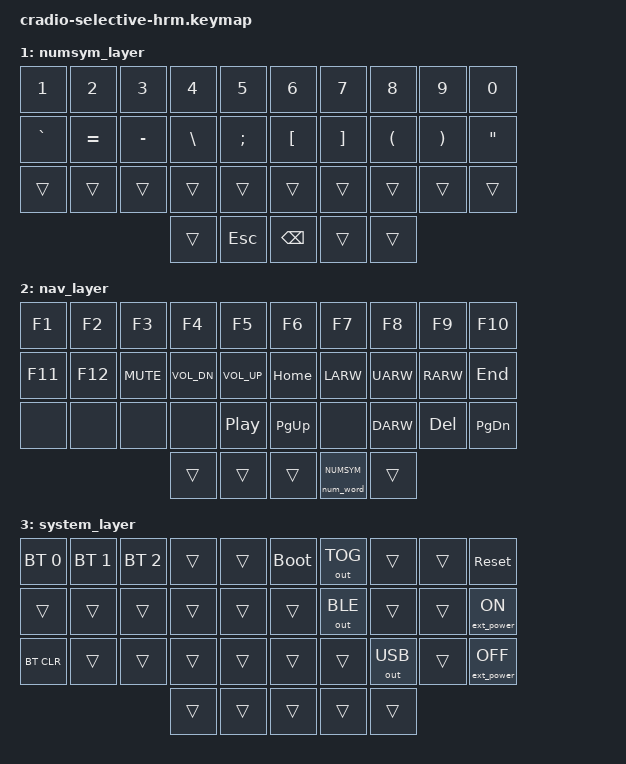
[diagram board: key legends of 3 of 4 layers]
// Copyright (c) 2022 The ZMK Contributors
// SPDX-License-Identifier: MIT
//
// OPTION 2: SELECTIVE HOME ROW MODS (RECOMMENDED)
// - SHIFT moved to left thumb (sticky behavior)
// - CTRL added to right thumb cluster for vim
// - Only CMD/ALT remain on home row (with longer delays)
// - Panic mode for layer recovery
// - Solves the biggest HRM typing interference issues

#include <behaviors/num_word.dtsi>
#include <behaviors.dtsi>
#include <dt-bindings/zmk/keys.h>
#include <dt-bindings/zmk/bt.h>
#include <dt-bindings/zmk/outputs.h>
#include <dt-bindings/zmk/ext_power.h>

// ---------- Layer indexes ----------
#define BASE    0 
#define NUMSYM  1
#define NAV     2
#define SYSTEM  3

// ---------- Reduced Home-row Mods (CMD/ALT only) ----------
#define HRML_LITE(k1,k2,k3,k4) &kp k1  &ht_slow LALT k2   &kp k3   &ht_slow LGUI k4
#define HRMR_LITE(k1,k2,k3,k4) &ht_slow RGUI k1   &kp k2  &ht_slow RALT k3    &kp k4

/ {
    behaviors {
        // Standard hold-tap for layer access
        ht: hold_tap {
            compatible = "zmk,behavior-hold-tap";
            #binding-cells = <2>;
            flavor = "tap-preferred";
            tapping-term-ms = <200>;
            quick-tap-ms = <120>;
            require-prior-idle-ms = <100>;
            bindings = <&kp>, <&kp>;
        };

        // Slower hold-tap for remaining home row mods to prevent roll interference
        ht_slow: hold_tap_slow {
            compatible = "zmk,behavior-hold-tap";
            #binding-cells = <2>;
            flavor = "tap-preferred";
            tapping-term-ms = <280>;  // Longer delay
            quick-tap-ms = <100>;
            require-prior-idle-ms = <150>;  // More idle time
            bindings = <&kp>, <&kp>;
        };

        // Sticky SHIFT - tap for next key, hold for continuous
        sk_lshft: sticky_shift {
            compatible = "zmk,behavior-sticky-key";
            #binding-cells = <1>;
            bindings = <&kp>;
            release-after-ms = <1000>;
            quick-release;
        };

        // Sticky CTRL for vim workflows
        sk_lctrl: sticky_ctrl {
            compatible = "zmk,behavior-sticky-key";
            #binding-cells = <1>;
            bindings = <&kp>;
            release-after-ms = <1000>;
            quick-release;
        };

        // Multi-function thumb key: hold for sticky, tap for regular
        mt_shift: mod_tap_shift {
            compatible = "zmk,behavior-hold-tap";
            #binding-cells = <2>;
            flavor = "tap-preferred";
            tapping-term-ms = <200>;
            quick-tap-ms = <120>;
            require-prior-idle-ms = <100>;
            bindings = <&sk_lshft>, <&kp>;
        };

        mt_ctrl: mod_tap_ctrl {
            compatible = "zmk,behavior-hold-tap";
            #binding-cells = <2>;
            flavor = "tap-preferred";
            tapping-term-ms = <200>;
            quick-tap-ms = <120>;
            require-prior-idle-ms = <100>;
            bindings = <&sk_lctrl>, <&kp>;
        };
    };

    // ---------- Combos for enhanced functionality ----------
    combos {
        compatible = "zmk,combos";
        
        // Panic mode - double thumb tap returns to base
        combo_panic {
            timeout-ms = <50>;
            key-positions = <30 33>;
            bindings = <&to BASE>;
            layers = <BASE NUMSYM NAV SYSTEM>;
        };

        // Common shortcuts as combos
        combo_enter {
            timeout-ms = <40>;
            key-positions = <17 18 19>; // J K L
            bindings = <&kp ENTER>;
            layers = <BASE>;
        };

        combo_hyphen {
            timeout-ms = <40>;
            key-positions = <22 23>; // C V
            bindings = <&kp MINUS>;
            layers = <BASE>;
        };

        combo_underscore {
            timeout-ms = <40>;
            key-positions = <22 23>; // C V
            bindings = <&kp UNDER>;
            layers = <NUMSYM>;
        };
    };

    // ---------- Conditional tri-layer ----------
    conditional_layers {
        compatible = "zmk,conditional-layers";
        system_layer {
            if-layers = <NAV NUMSYM>;
            then-layer = <SYSTEM>;
        };
    };

    keymap {
        compatible = "zmk,keymap";
        base_layer {
            bindings = <
        //╭──────────┬──────────┬──────────┬──────────┬──────────╮   ╭──────────┬──────────┬──────────┬──────────┬──────────╮
        //│  Q       │  W       │  E       │  R       │  T       │   │  Y       │  U       │  I       │  O       │  P       │
             &kp Q      &kp W      &kp E      &kp R      &kp T          &kp Y      &kp U      &kp I      &kp O      &kp P
        //├──────────┼──────────┼──────────┼──────────┼──────────┤   ├──────────┼──────────┼──────────┼──────────┼──────────┤
        //│  A       │  S       │  D       │  F       │  G       │   │  H       │  J       │  K       │  L       │ ' "      │
             HRML_LITE(A, S,       D,         F)         &kp G          &kp H      HRMR_LITE(J, K,       L,        SQT)
        //├──────────┼──────────┼──────────┼──────────┼──────────┤   ├──────────┼──────────┼──────────┼──────────┼──────────┤
        //│  Z       │  X       │  C       │  V       │  B       │   │  N       │  M       │ , <      │ . >      │ / ?      │
            &kp Z      &kp X      &kp C      &kp V      &kp B          &kp N      &kp M      &kp COMMA  &kp DOT    &kp FSLH
        //╰──────────┴──────────┴──────────┼──────────┼──────────┤   ├──────────┼──────────┼──────────┴──────────┴──────────╯
                                    &mt_shift LSHFT &lt NAV TAB     &kp ENTER  &mt_ctrl LCTRL &lt NUMSYM SPACE
        //                                 ╰──────────┴──────────╯   ╰──────────┴──────────╯
            >;
        };

        numsym_layer {
            bindings = <
        //╭──────────┬──────────┬──────────┬──────────┬──────────╮   ╭──────────┬──────────┬──────────┼──────────┬──────────╮
        //│ 1        │ 2        │ 3        │ 4        │ 5        │   │ 6        │ 7        │ 8        │ 9        │  0       │
            &kp N1     &kp N2     &kp N3     &kp N4     &kp N5         &kp N6     &kp N7     &kp N8     &kp N9     &kp N0
        //├──────────┼──────────┼──────────┼──────────┼──────────┤   ├──────────┼──────────┼──────────┼──────────┼──────────┤
        //│ ` ~      │ = +      │ - _      │  \ |     │  ; :     │   │ [ {      │ ] }      │ ( )      │ ) }      │  " '     │
            &kp GRAVE  &kp EQUAL  &kp MINUS  &kp BSLH   &kp SEMI       &kp LBKT   &kp RBKT   &kp LPAR   &kp RPAR   &kp DQT
        //├──────────┼──────────┼──────────┼──────────┼──────────┤   ├──────────┼──────────┼──────────┼──────────┼──────────┤
        //│          │          │          │          │          │   │          │          │          │          │          │
            &trans     &trans     &trans     &trans     &trans         &trans     &trans     &trans     &trans     &trans
        //╰──────────┴──────────┴──────────┼──────────┼──────────┤   ├──────────┼──────────┼──────────┴──────────┴──────────╯
                                                &trans     &kp ESC        &kp BSPC     &trans     &trans
        //                                 ╰──────────┴──────────╯   ╰──────────┴──────────╯
            >;
        };

        nav_layer {
            bindings = <
        //╭──────────┬──────────┬──────────┬──────────┬──────────╮   ╭──────────┬──────────┬──────────┬──────────┬──────────╮
        //│  F1      │  F2      │  F3      │  F4      │ F5       │   │  F6      │  F7      │  F8      │  F9      │  F10     │
             &kp F1     &kp F2     &kp F3     &kp F4    &kp F5          &kp F6     &kp F7     &kp F8     &kp F9     &kp F10
        //├──────────┼──────────┼──────────┼──────────┼──────────┤   ├──────────┼──────────┼──────────┼──────────┼──────────┤
        //│  F11     │  F12     │  Mute    │  VOL DN  │ VOL UP   │   │  HOME    │  LEFT    │  UP      │ RIGHT    │   END    │
             &kp F11    &kp F12   &kp K_MUTE &kp C_VOL_DN &kp C_VOL_UP   &kp HOME   &kp LARW   &kp UARW   &kp RARW   &kp END
        //├──────────┼──────────┼──────────┼──────────┼──────────┤   ├──────────┼──────────┼──────────┼──────────┼──────────┤
        //│          │          │          │          │ PLAY     │   │ PAGE_UP  │          │ DOWN     │   DEL    │ PAGE_DN  │
             &none     &none       &none      &none     &kp C_PP        &kp PG_UP  &none      &kp DARW   &kp DEL    &kp PG_DN
        //╰──────────┴──────────┴──────────┼──────────┼──────────┤   ├──────────┼──────────┼──────────┴──────────┴──────────╯
                                                 &trans     &trans         &trans     &num_word NUMSYM &trans
        //                                 ╰──────────┴──────────╯   ╰──────────┴──────────╯
            >;
        };

        system_layer {
            bindings = <
        //╭──────────┬──────────┬──────────┬──────────┬──────────╮   ╭──────────┬──────────┬──────────┬──────────┬──────────╮
        //│ PROFILE 0│ PROFILE 1│PROFILE 2 │          │		 │   │BOOTLOADER│          │          │          │  RESET   │
        &bt BT_SEL 0  &bt BT_SEL 1 &bt BT_SEL 2 &trans  	&trans        &bootloader &out OUT_TOG &trans      &trans   &sys_reset
        //├──────────┼──────────┼──────────┼──────────┼──────────┤   ├──────────┼──────────┼──────────┼──────────┼──────────┤
        //│          │          │          │          │          │   │          │          │          │          │EP ON     │
           &trans      &trans     &trans     &trans    &trans          &trans &out OUT_BLE     &trans     &trans  &ext_power EP_ON
        //├──────────┼──────────┼──────────┼──────────┼──────────┤   ├──────────┼──────────┼──────────┼──────────┼──────────┤
        //│ CLEAR BT │          │          │          │	         │   │          │          │          │          │EP OFF    │
           &bt BT_CLR  &trans     &trans    &trans	&trans          &trans     &trans   &out OUT_USB  &trans  &ext_power EP_OFF
        //╰──────────┴──────────┴──────────┼──────────┼──────────┤   ├──────────┼──────────┼──────────┴──────────┴──────────╯
                                          &trans     &trans         &trans     &trans     &trans
        //                                 ╰──────────┴──────────╯   ╰──────────┴──────────╯
            >;
        };
    };
};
